# f28004x_sdfm_regs register map
Vendor: Texas Instruments
Peripheral module from a debugger description file (folder C2000).
Address unit: 16 bits
Registers are 16-bit, read-write, no defined reset value unless marked. A register's access mark holds for its fields unless they carry their own. Offsets are as the file gives them; lines under a group give offsets from that group; [hi:lo] are bit positions; {n}, {i} and the like mark numbered series; 'fields as' and 'values as' point back to an identical list; <NAME> marks a mode.

## SDFM_REGS — SDFM Registers
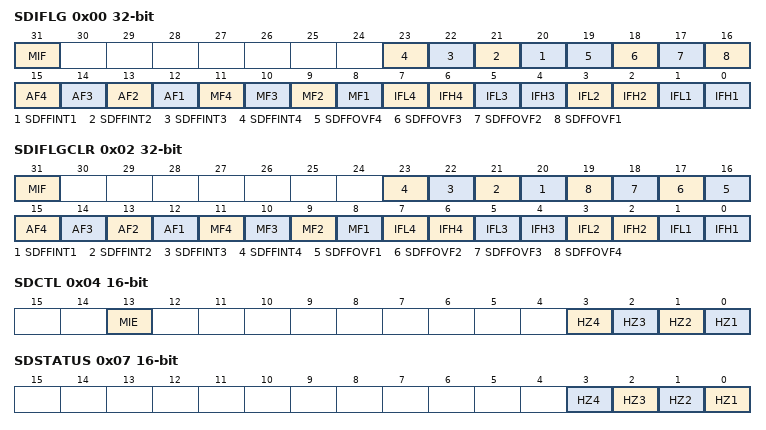
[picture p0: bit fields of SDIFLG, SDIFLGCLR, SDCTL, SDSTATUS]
0x00 SDIFLG 32-bit ro — SD Interrupt Flag Register
  [31] MIF — Master Interrupt Flag
  [n+19] SDFFINT{n} (n=1..4) — SDFIFO interrupt for Ch{n}
  [19] SDFFOVF4 — FIFO Overflow Flag for Ch4
  [18] SDFFOVF3 — FIFO Overflow Flag for Ch3
  [17] SDFFOVF2 — FIFO Overflow Flag for Ch2
  [16] SDFFOVF1 — FIFO Overflow Flag for Ch1.
  [n+11] AF{n} (n=1..4) — Acknowledge flag for Filter {n}
  [n+7] MF{n} (n=1..4) — Modulator Failure for Filter {n}
  [2n-1] IFL{n} (n=1..4) — Low-level Interrupt flag for Ch{n}
  [2n-2] IFH{n} (n=1..4) — High-level Interrupt flag for Ch{n}
0x02 SDIFLGCLR 32-bit access not given — SD Interrupt Flag Clear Register
  [31] MIF — Master Interrupt Flag (access R=0/W=1)
  [n+19] SDFFINT{n} (n=1..4) — SDFIFO Interrupt flag-clear bit for Ch{n} (access R=0/W=1)
  [n+15] SDFFOVF{n} (n=1..4) — SDFIFO overflow clear Ch{n} (access R=0/W=1)
  [n+11] AF{n} (n=1..4) — Acknowledge flag for Filter {n} (access R=0/W=1)
  [n+7] MF{n} (n=1..4) — Modulator Failure for Filter {n} (access R=0/W=1)
  [2n-1] IFL{n} (n=1..4) — Low-level Interrupt flag for Ch{n} (access R=0/W=1)
  [2n-2] IFH{n} (n=1..4) — High-level Interrupt flag for Ch{n} (access R=0/W=1)
0x04 SDCTL access not given — SD Control Register
  [13] MIE rw — Master SDy_ERR Interrupt enable
  [n-1] HZ{n} (n=1..4) — High-level Threshold crossing (Z) flag Ch{n} (access R=0/W=1)
0x06 SDMFILEN — SD Master Filter Enable
  [11] MFE — Master Filter Enable.
0x07 SDSTATUS ro
  [n-1] HZ{n} (n=1..4) — High-level Threshold crossing (Z) flag Ch{n}
{0x0+0x10*i} SDCTLPARM{i} (i=1..4) — Control Parameter Register for Ch{i}
  [1:0] MOD — Modulator clocking modes
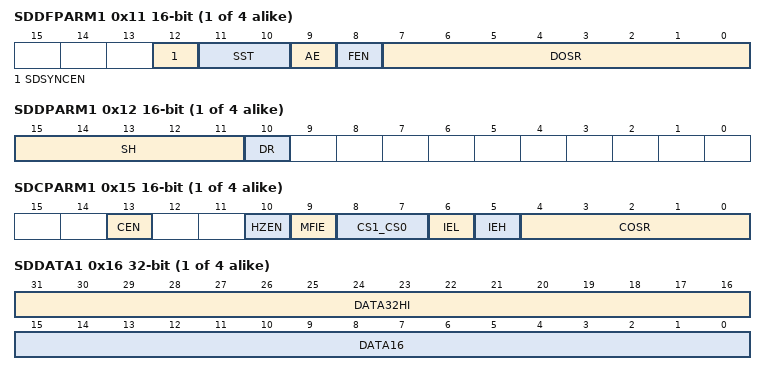
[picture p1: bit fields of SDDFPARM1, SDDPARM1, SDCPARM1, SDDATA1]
{0x1+0x10*i} SDDFPARM{i} (i=1..4) — Data Filter Parameter Register for Ch{i}
  [12] SDSYNCEN — Data Filter Reset Enable
  [11:10] SST — Data filter Structure (SincFast/1/2/3)
  [9] AE — Ack Enable
  [8] FEN — Filter Enable
  [7:0] DOSR — Data Filter Oversample Ratio= DOSR+1
{0x2+0x10*i} SDDPARM{i} (i=1..4) — Data Parameter Register for Ch{i}
  [15:11] SH — Shift Control (# bits to shift in 16b mode)
  [10] DR — Data Representation (0/1 = 16/32b 2's complement)
{0x3+0x10*i} SDCMPH{i} (i=1..4) — High-level Threshold Register for Ch{i}
  [14:0] HLT — High-level threshold for the comparator filter output
{0x4+0x10*i} SDCMPL{i} (i=1..4) — Low-level Threshold Register for Ch{i}
  [14:0] LLT — Low-level threshold for the comparator filter output
{0x5+0x10*i} SDCPARM{i} (i=1..4) — Comparator Filter Parameter Register for Ch{i}
  [13] CEN — Comparator Enable
  [10] HZEN — High level (Z) Threshold crossing output enable
  [9] MFIE — Modulator Failure Interrupt enable
  [8:7] CS1_CS0 — Comparator Filter Structure (SincFast/1/2/3)
  [6] IEL — Low-level interrupt enable
  [5] IEH — High-level Interrupt enable.
  [4:0] COSR — Comparator Oversample Ratio. Actual rate COSR+1
{0x6+0x10*i} SDDATA{i} 32-bit ro (i=1..4) — Data Filter Data Register (16 or 32bit) for Ch{i}
  [31:16] DATA32HI — Hi-order 16b in 32b mode, 16-bit Data in 16b mode
  [15:0] DATA16 — Lo-order 16b in 32b mode
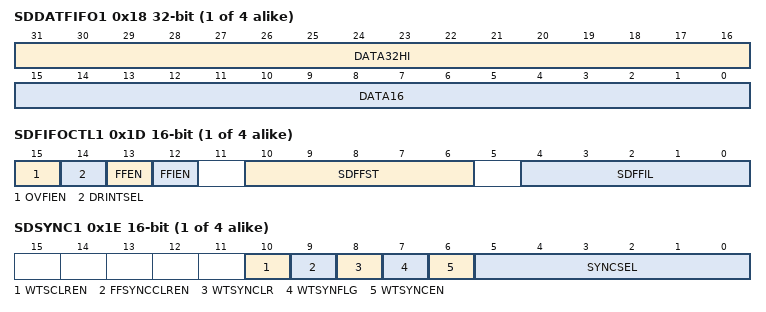
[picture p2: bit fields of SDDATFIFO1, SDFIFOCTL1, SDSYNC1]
{0x8+0x10*i} SDDATFIFO{i} 32-bit ro (i=1..4) — Filter Data FIFO Output(32b) for Ch{i}
  fields as SDDATA1
{0xA+0x10*i} SDCDATA{i} ro (i=1..4) — Comparator Filter Data Register (16b) for Ch{i}
  [15:0] DATA16 — Comparator Data output - 16b only
{0xC+0x10*i} SDCMPHZ{i} (i=1..4) — High-level (Z) Threshold Register for Ch{i}
  [14:0] HLTZ — High-level threshold (Z) for the comparator filter output
{0xD+0x10*i} SDFIFOCTL{i} access per field (i=1..4) — FIFO Control Register for Ch{i}
  [15] OVFIEN rw — SDFIFO Overflow interrupt enable
  [14] DRINTSEL rw — Data-Ready Interrupt Source Select
  [13] FFEN rw — SDFIFO Enable
  [12] FFIEN rw — SDFIFO data ready Interrupt Enable
  [10:6] SDFFST ro — SDFIFO Status
  [4:0] SDFFIL rw — SDFIFO Interrupt Level
{0xE+0x10*i} SDSYNC{i} access not given (i=1..4) — SD Filter Sync control for Ch{i}
  [10] WTSCLREN rw — WTSYNFLG Clear-on-FIFOINT Enable
  [9] FFSYNCCLREN rw — FIFO Clear-on-SDSYNC Enable
  [8] WTSYNCLR — Wait-for-Sync Flag Clear (access R=0/W)
  [7] WTSYNFLG ro — Wait-for-Sync Flag
  [6] WTSYNCEN rw — Wait-for-Sync Enable
  [5:0] SYNCSEL rw — SDSYNC Source Select
